# PIC32MX470F512L register map
Vendor: Microchip
Registers are 32-bit, read-write, reset 0x0 unless marked. A register's access mark holds for its fields unless they carry their own. Addresses are absolute, and some are shared; only a register's first bit layout is shown; [hi:lo] are bit positions; {n}, {i} and the like mark numbered series.

## PORTD
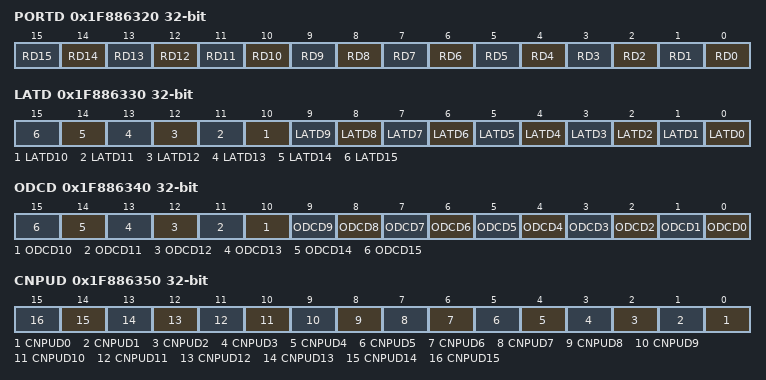
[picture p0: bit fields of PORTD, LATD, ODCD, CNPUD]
0x1F886320 PORTD reset not defined — (power-on value ----------------xxxxxxxxxxxxxxxx)
  [n] RD{n} (n=0..15)
0x1F886330 LATD reset not defined — (power-on value ----------------xxxxxxxxxxxxxxxx)
  [n] LATD{n} (n=0..15)
0x1F886340 ODCD
  [n] ODCD{n} (n=0..15)
0x1F886350 CNPUD reset not defined — (power-on value ----------------xxxxxxxxxxxxxxxx)
  [n] CNPUD{n} (n=0..15)
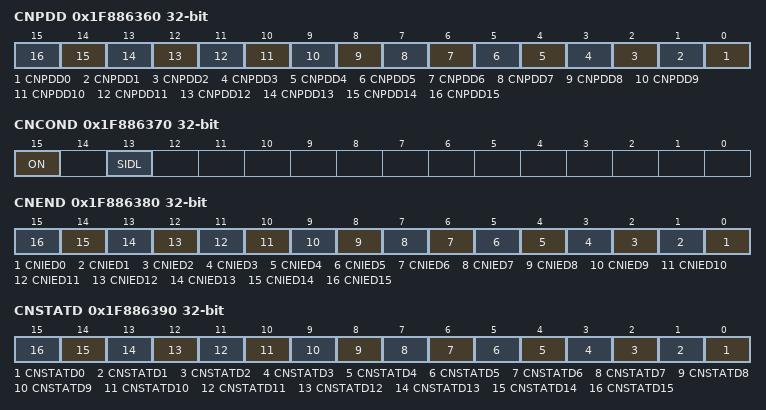
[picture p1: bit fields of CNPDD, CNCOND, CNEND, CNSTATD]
0x1F886360 CNPDD reset not defined — (power-on value ----------------xxxxxxxxxxxxxxxx)
  [n] CNPDD{n} (n=0..15)
0x1F886370 CNCOND
  [15] ON, [13] SIDL
0x1F886380 CNEND reset not defined — (power-on value 0000000000------xxxxxxxxxxxxxxxx)
  [n] CNIED{n} (n=0..15)
0x1F886390 CNSTATD reset not defined — (power-on value ----------------xxxxxxxxxxxxxxxx)
  [n] CNSTATD{n} (n=0..15)

## PORTE
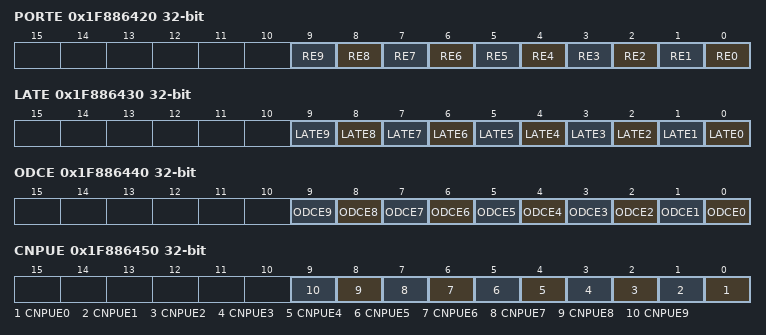
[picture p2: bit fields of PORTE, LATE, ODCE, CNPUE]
0x1F886420 PORTE reset not defined — (power-on value ----------------------xxxxxxxxxx)
  [n] RE{n} (n=0..9)
0x1F886430 LATE reset not defined — (power-on value ----------------------xxxxxxxxxx)
  [n] LATE{n} (n=0..9)
0x1F886440 ODCE
  [n] ODCE{n} (n=0..9)
0x1F886450 CNPUE reset not defined — (power-on value ----------------------xxxxxxxxxx)
  [n] CNPUE{n} (n=0..9)
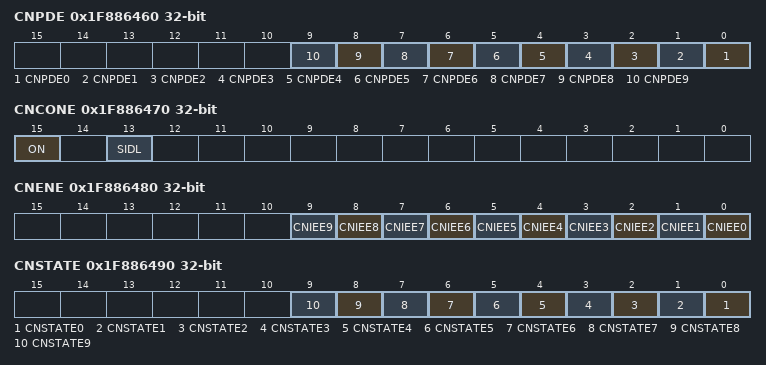
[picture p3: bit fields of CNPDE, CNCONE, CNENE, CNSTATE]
0x1F886460 CNPDE reset not defined — (power-on value ----------------------xxxxxxxxxx)
  [n] CNPDE{n} (n=0..9)
0x1F886470 CNCONE
  [15] ON, [13] SIDL
0x1F886480 CNENE reset not defined — (power-on value 0000000000------------xxxxxxxxxx)
  [n] CNIEE{n} (n=0..9)
0x1F886490 CNSTATE reset not defined — (power-on value ----------------------xxxxxxxxxx)
  [n] CNSTATE{n} (n=0..9)

## PORTF
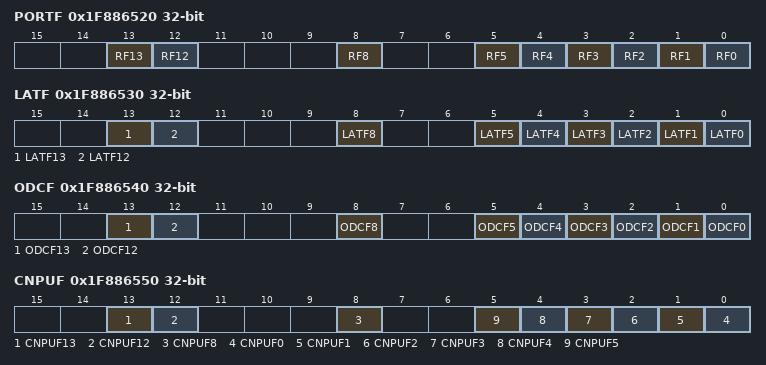
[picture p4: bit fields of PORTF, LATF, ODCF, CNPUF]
0x1F886520 PORTF reset not defined — (power-on value ------------------xx---x--xxxxxx)
  [13] RF13, [12] RF12, [8] RF8, [n] RF{n} (n=0..5)
0x1F886530 LATF reset not defined — (power-on value ------------------xx---x--xxxxxx)
  [13] LATF13, [12] LATF12, [8] LATF8, [n] LATF{n} (n=0..5)
0x1F886540 ODCF
  [13] ODCF13, [12] ODCF12, [8] ODCF8, [n] ODCF{n} (n=0..5)
0x1F886550 CNPUF reset not defined — (power-on value ------------------xx---x--xxxxxx)
  [13] CNPUF13, [12] CNPUF12, [8] CNPUF8, [n] CNPUF{n} (n=0..5)
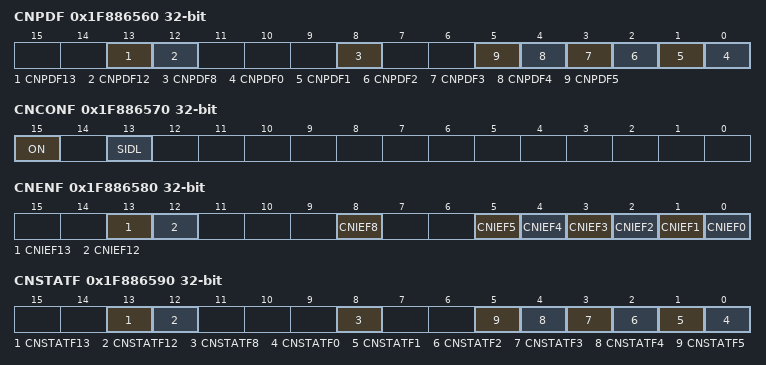
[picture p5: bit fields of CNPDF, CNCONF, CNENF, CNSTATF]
0x1F886560 CNPDF reset not defined — (power-on value ------------------xx---x--xxxxxx)
  [13] CNPDF13, [12] CNPDF12, [8] CNPDF8, [n] CNPDF{n} (n=0..5)
0x1F886570 CNCONF
  [15] ON, [13] SIDL
0x1F886580 CNENF reset not defined — (power-on value 0000000000--------xx---x--xxxxxx)
  [13] CNIEF13, [12] CNIEF12, [8] CNIEF8, [n] CNIEF{n} (n=0..5)
0x1F886590 CNSTATF reset not defined — (power-on value ------------------xx---x--xxxxxx)
  [13] CNSTATF13, [12] CNSTATF12, [8] CNSTATF8, [n] CNSTATF{n} (n=0..5)

## PORTG
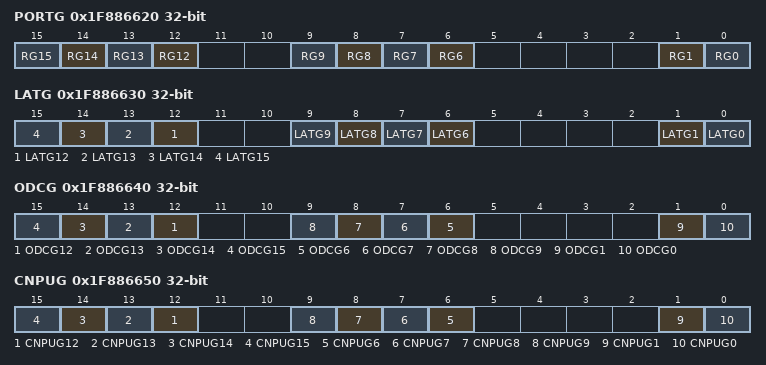
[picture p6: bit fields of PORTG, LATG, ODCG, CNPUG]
0x1F886620 PORTG reset not defined — (power-on value ----------------xxxx--xxxx----xx)
  [n] RG{n} (n=12..15), [n] RG{n} (n=6..9), [1] RG1, [0] RG0
0x1F886630 LATG reset not defined — (power-on value ----------------xxxx--xxxx----xx)
  [n] LATG{n} (n=12..15), [n] LATG{n} (n=6..9), [1] LATG1, [0] LATG0
0x1F886640 ODCG
  [n] ODCG{n} (n=12..15), [n] ODCG{n} (n=6..9), [1] ODCG1, [0] ODCG0
0x1F886650 CNPUG reset not defined — (power-on value ----------------xxxx--xxxx----xx)
  [n] CNPUG{n} (n=12..15), [n] CNPUG{n} (n=6..9), [1] CNPUG1, [0] CNPUG0
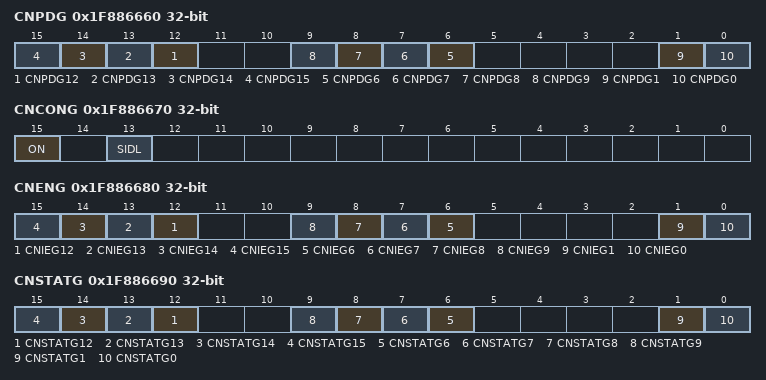
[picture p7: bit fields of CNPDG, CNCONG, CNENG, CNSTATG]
0x1F886660 CNPDG reset not defined — (power-on value ----------------xxxx--xxxx----xx)
  [n] CNPDG{n} (n=12..15), [n] CNPDG{n} (n=6..9), [1] CNPDG1, [0] CNPDG0
0x1F886670 CNCONG
  [15] ON, [13] SIDL
0x1F886680 CNENG reset not defined — (power-on value 0000000000------xxxx--xxxx----xx)
  [n] CNIEG{n} (n=12..15), [n] CNIEG{n} (n=6..9), [1] CNIEG1, [0] CNIEG0
0x1F886690 CNSTATG reset not defined — (power-on value ----------------xxxx--xxxx----xx)
  [n] CNSTATG{n} (n=12..15), [n] CNSTATG{n} (n=6..9), [1] CNSTATG1, [0] CNSTATG0
